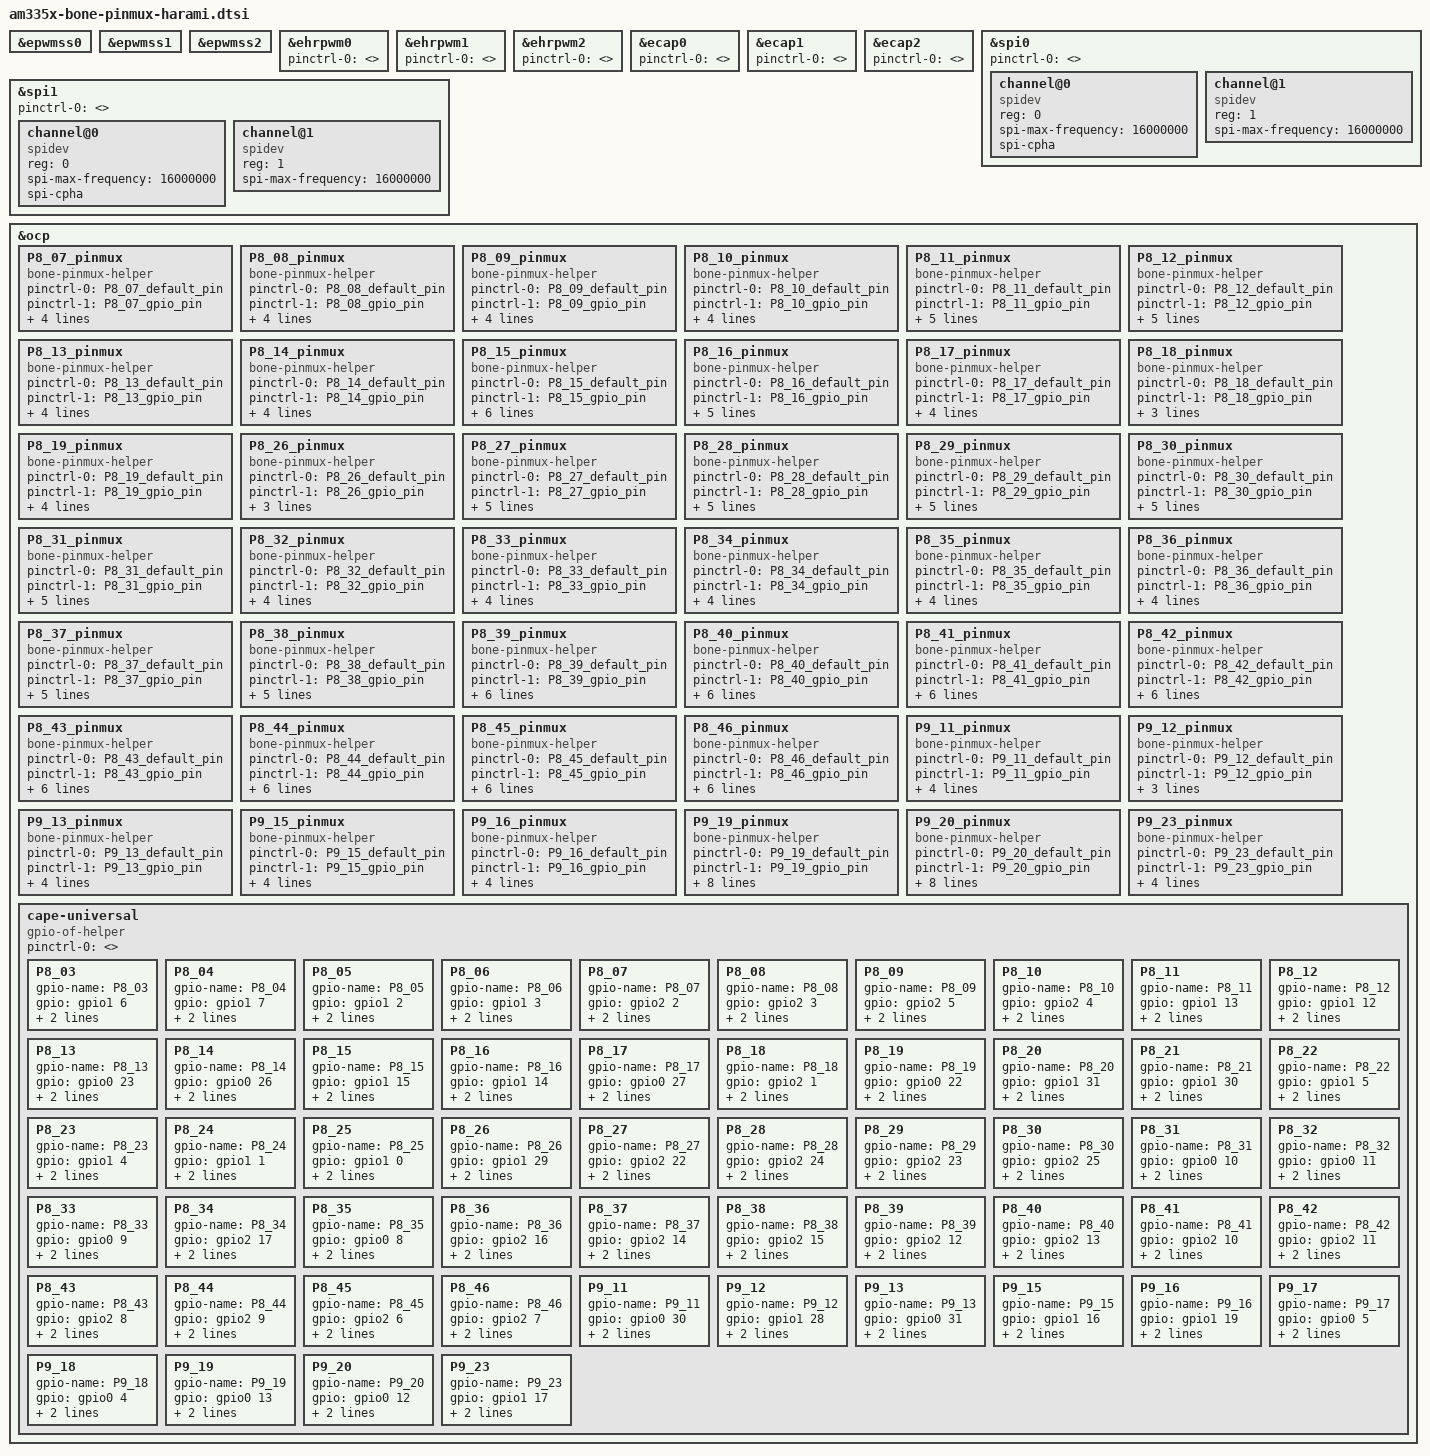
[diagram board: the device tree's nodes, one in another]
&epwmss0 {
	status = "okay";
};

&epwmss1 {
	status = "okay";
};

&epwmss2 {
	status = "okay";
};

&ehrpwm0 {
	status = "okay";
	pinctrl-names = "default";
	pinctrl-0 = <>;
};

&ehrpwm1 {
	status = "okay";
	pinctrl-names = "default";
	pinctrl-0 = <>;
};

&ehrpwm2 {
	status = "okay";
	pinctrl-names = "default";
	pinctrl-0 = <>;
};

&ecap0 {
	status = "okay";
	pinctrl-names = "default";
	pinctrl-0 = <>;
};

&ecap1 {
	status = "okay";
	pinctrl-names = "default";
	pinctrl-0 = <>;
};

&ecap2 {
	status = "okay";
	pinctrl-names = "default";
	pinctrl-0 = <>;
};

&spi0 {
	status = "okay";
	pinctrl-names = "default";
	pinctrl-0 = <>;

	channel@0 {
		#address-cells = <1>;
		#size-cells = <0>;

		compatible = "spidev";

		reg = <0>;
		spi-max-frequency = <16000000>;
		spi-cpha;
	};

	channel@1 {
		#address-cells = <1>;
		#size-cells = <0>;

		compatible = "spidev";

		reg = <1>;
		spi-max-frequency = <16000000>;
	};
};

&spi1 {
	status = "okay";
	pinctrl-names = "default";
	pinctrl-0 = <>;

	channel@0 {
		#address-cells = <1>;
		#size-cells = <0>;

		compatible = "spidev";

		reg = <0>;
		spi-max-frequency = <16000000>;
		spi-cpha;
	};

	channel@1 {
		#address-cells = <1>;
		#size-cells = <0>;

		compatible = "spidev";

		reg = <1>;
		spi-max-frequency = <16000000>;
	};
};

/**********************************************************************/
/* Pin Multiplex Helpers                                              */
/*                                                                    */
/* These provide userspace runtime pin configuration for the          */
/* BeagleBone cape expansion headers                                  */
/**********************************************************************/

&ocp {
	/************************/
	/* P8 Header */
	/************************/

	/* P8_01                GND */

	/* P8_02                GND */

	/* P8_03 (ZCZ ball R9) emmc */

	/* P8_04 (ZCZ ball T9) emmc */

	/* P8_05 (ZCZ ball R8) emmc */

	/* P8_06 (ZCZ ball T8) emmc */

	/* P8_07 (ZCZ ball R7) */
	P8_07_pinmux {
		compatible = "bone-pinmux-helper";
		status = "okay";
		pinctrl-names = "default", "gpio", "gpio_pu", "gpio_pd", "gpio_input", "timer";
		pinctrl-0 = <&P8_07_default_pin>;
		pinctrl-1 = <&P8_07_gpio_pin>;
		pinctrl-2 = <&P8_07_gpio_pu_pin>;
		pinctrl-3 = <&P8_07_gpio_pd_pin>;
		pinctrl-4 = <&P8_07_gpio_input_pin>;
		pinctrl-5 = <&P8_07_timer_pin>;
	};

	/* P8_08 (ZCZ ball T7) */
	P8_08_pinmux {
		compatible = "bone-pinmux-helper";
		status = "okay";
		pinctrl-names = "default", "gpio", "gpio_pu", "gpio_pd", "gpio_input", "timer";
		pinctrl-0 = <&P8_08_default_pin>;
		pinctrl-1 = <&P8_08_gpio_pin>;
		pinctrl-2 = <&P8_08_gpio_pu_pin>;
		pinctrl-3 = <&P8_08_gpio_pd_pin>;
		pinctrl-4 = <&P8_08_gpio_input_pin>;
		pinctrl-5 = <&P8_08_timer_pin>;
	};

	/* P8_09 (ZCZ ball T6) */
	P8_09_pinmux {
		compatible = "bone-pinmux-helper";
		status = "okay";
		pinctrl-names = "default", "gpio", "gpio_pu", "gpio_pd", "gpio_input", "timer";
		pinctrl-0 = <&P8_09_default_pin>;
		pinctrl-1 = <&P8_09_gpio_pin>;
		pinctrl-2 = <&P8_09_gpio_pu_pin>;
		pinctrl-3 = <&P8_09_gpio_pd_pin>;
		pinctrl-4 = <&P8_09_gpio_input_pin>;
		pinctrl-5 = <&P8_09_timer_pin>;
	};

	/* P8_10 (ZCZ ball U6) */
	P8_10_pinmux {
		compatible = "bone-pinmux-helper";
		status = "okay";
		pinctrl-names = "default", "gpio", "gpio_pu", "gpio_pd", "gpio_input", "timer";
		pinctrl-0 = <&P8_10_default_pin>;
		pinctrl-1 = <&P8_10_gpio_pin>;
		pinctrl-2 = <&P8_10_gpio_pu_pin>;
		pinctrl-3 = <&P8_10_gpio_pd_pin>;
		pinctrl-4 = <&P8_10_gpio_input_pin>;
		pinctrl-5 = <&P8_10_timer_pin>;
	};

	/* P8_11 (ZCZ ball R12) */
	P8_11_pinmux {
		compatible = "bone-pinmux-helper";
		status = "okay";
		pinctrl-names = "default", "gpio", "gpio_pu", "gpio_pd", "gpio_input", "qep", "pruout";
		pinctrl-0 = <&P8_11_default_pin>;
		pinctrl-1 = <&P8_11_gpio_pin>;
		pinctrl-2 = <&P8_11_gpio_pu_pin>;
		pinctrl-3 = <&P8_11_gpio_pd_pin>;
		pinctrl-4 = <&P8_11_gpio_input_pin>;
		pinctrl-5 = <&P8_11_qep_pin>;
		pinctrl-6 = <&P8_11_pruout_pin>;
	};

	/* P8_12 (ZCZ ball T12) */
	P8_12_pinmux {
		compatible = "bone-pinmux-helper";
		status = "okay";
		pinctrl-names = "default", "gpio", "gpio_pu", "gpio_pd", "gpio_input", "qep", "pruout";
		pinctrl-0 = <&P8_12_default_pin>;
		pinctrl-1 = <&P8_12_gpio_pin>;
		pinctrl-2 = <&P8_12_gpio_pu_pin>;
		pinctrl-3 = <&P8_12_gpio_pd_pin>;
		pinctrl-4 = <&P8_12_gpio_input_pin>;
		pinctrl-5 = <&P8_12_qep_pin>;
		pinctrl-6 = <&P8_12_pruout_pin>;
	};

	/* P8_13 (ZCZ ball T10) */
	P8_13_pinmux {
		compatible = "bone-pinmux-helper";
		status = "okay";
		pinctrl-names = "default", "gpio", "gpio_pu", "gpio_pd", "gpio_input", "pwm";
		pinctrl-0 = <&P8_13_default_pin>;
		pinctrl-1 = <&P8_13_gpio_pin>;
		pinctrl-2 = <&P8_13_gpio_pu_pin>;
		pinctrl-3 = <&P8_13_gpio_pd_pin>;
		pinctrl-4 = <&P8_13_gpio_input_pin>;
		pinctrl-5 = <&P8_13_pwm_pin>;
	};

	/* P8_14 (ZCZ ball T11) */
	P8_14_pinmux {
		compatible = "bone-pinmux-helper";
		status = "okay";
		pinctrl-names = "default", "gpio", "gpio_pu", "gpio_pd", "gpio_input", "pwm";
		pinctrl-0 = <&P8_14_default_pin>;
		pinctrl-1 = <&P8_14_gpio_pin>;
		pinctrl-2 = <&P8_14_gpio_pu_pin>;
		pinctrl-3 = <&P8_14_gpio_pd_pin>;
		pinctrl-4 = <&P8_14_gpio_input_pin>;
		pinctrl-5 = <&P8_14_pwm_pin>;
	};

	/* P8_15 (ZCZ ball U13) */
	P8_15_pinmux {
		compatible = "bone-pinmux-helper";
		status = "okay";
		pinctrl-names = "default", "gpio", "gpio_pu", "gpio_pd", "gpio_input", "qep", "pru_ecap", "pruin";
		pinctrl-0 = <&P8_15_default_pin>;
		pinctrl-1 = <&P8_15_gpio_pin>;
		pinctrl-2 = <&P8_15_gpio_pu_pin>;
		pinctrl-3 = <&P8_15_gpio_pd_pin>;
		pinctrl-4 = <&P8_15_gpio_input_pin>;
		pinctrl-5 = <&P8_15_qep_pin>;
		pinctrl-6 = <&P8_15_pru_ecap_pin>;
		pinctrl-7 = <&P8_15_pruin_pin>;
	};

	/* P8_16 (ZCZ ball V13) */
	P8_16_pinmux {
		compatible = "bone-pinmux-helper";
		status = "okay";
		pinctrl-names = "default", "gpio", "gpio_pu", "gpio_pd", "gpio_input", "qep", "pruin";
		pinctrl-0 = <&P8_16_default_pin>;
		pinctrl-1 = <&P8_16_gpio_pin>;
		pinctrl-2 = <&P8_16_gpio_pu_pin>;
		pinctrl-3 = <&P8_16_gpio_pd_pin>;
		pinctrl-4 = <&P8_16_gpio_input_pin>;
		pinctrl-5 = <&P8_16_qep_pin>;
		pinctrl-6 = <&P8_16_pruin_pin>;
	};

	/* P8_17 (ZCZ ball U12) */
	P8_17_pinmux {
		compatible = "bone-pinmux-helper";
		status = "okay";
		pinctrl-names = "default", "gpio", "gpio_pu", "gpio_pd", "gpio_input", "pwm";
		pinctrl-0 = <&P8_17_default_pin>;
		pinctrl-1 = <&P8_17_gpio_pin>;
		pinctrl-2 = <&P8_17_gpio_pu_pin>;
		pinctrl-3 = <&P8_17_gpio_pd_pin>;
		pinctrl-4 = <&P8_17_gpio_input_pin>;
		pinctrl-5 = <&P8_17_pwm_pin>;
	};

	/* P8_18 (ZCZ ball V12) */
	P8_18_pinmux {
		compatible = "bone-pinmux-helper";
		status = "okay";
		pinctrl-names = "default", "gpio", "gpio_pu", "gpio_pd", "gpio_input";
		pinctrl-0 = <&P8_18_default_pin>;
		pinctrl-1 = <&P8_18_gpio_pin>;
		pinctrl-2 = <&P8_18_gpio_pu_pin>;
		pinctrl-3 = <&P8_18_gpio_pd_pin>;
		pinctrl-4 = <&P8_18_gpio_input_pin>;
	};

	/* P8_19 (ZCZ ball U10) */
	P8_19_pinmux {
		compatible = "bone-pinmux-helper";
		status = "okay";
		pinctrl-names = "default", "gpio", "gpio_pu", "gpio_pd", "gpio_input", "pwm";
		pinctrl-0 = <&P8_19_default_pin>;
		pinctrl-1 = <&P8_19_gpio_pin>;
		pinctrl-2 = <&P8_19_gpio_pu_pin>;
		pinctrl-3 = <&P8_19_gpio_pd_pin>;
		pinctrl-4 = <&P8_19_gpio_input_pin>;
		pinctrl-5 = <&P8_19_pwm_pin>;
	};

	/* P8_20 (ZCZ ball V9) emmc */

	/* P8_21 (ZCZ ball U9) emmc */

	/* P8_22 (ZCZ ball V8) emmc */

	/* P8_23 (ZCZ ball U8) emmc */

	/* P8_24 (ZCZ ball V7) emmc */

	/* P8_25 (ZCZ ball U7) emmc */

	/* P8_26 (ZCZ ball V6) */
	P8_26_pinmux {
		compatible = "bone-pinmux-helper";
		status = "okay";
		pinctrl-names = "default", "gpio", "gpio_pu", "gpio_pd", "gpio_input";
		pinctrl-0 = <&P8_26_default_pin>;
		pinctrl-1 = <&P8_26_gpio_pin>;
		pinctrl-2 = <&P8_26_gpio_pu_pin>;
		pinctrl-3 = <&P8_26_gpio_pd_pin>;
		pinctrl-4 = <&P8_26_gpio_input_pin>;
	};

	/* P8_27 (ZCZ ball U5) hdmi */
	P8_27_pinmux {
		compatible = "bone-pinmux-helper";
		status = "okay";
		pinctrl-names = "default", "gpio", "gpio_pu", "gpio_pd", "gpio_input", "pruout", "pruin";
		pinctrl-0 = <&P8_27_default_pin>;
		pinctrl-1 = <&P8_27_gpio_pin>;
		pinctrl-2 = <&P8_27_gpio_pu_pin>;
		pinctrl-3 = <&P8_27_gpio_pd_pin>;
		pinctrl-4 = <&P8_27_gpio_input_pin>;
		pinctrl-5 = <&P8_27_pruout_pin>;
		pinctrl-6 = <&P8_27_pruin_pin>;
	};

	/* P8_28 (ZCZ ball V5) hdmi */
	P8_28_pinmux {
		compatible = "bone-pinmux-helper";
		status = "okay";
		pinctrl-names = "default", "gpio", "gpio_pu", "gpio_pd", "gpio_input", "pruout", "pruin";
		pinctrl-0 = <&P8_28_default_pin>;
		pinctrl-1 = <&P8_28_gpio_pin>;
		pinctrl-2 = <&P8_28_gpio_pu_pin>;
		pinctrl-3 = <&P8_28_gpio_pd_pin>;
		pinctrl-4 = <&P8_28_gpio_input_pin>;
		pinctrl-5 = <&P8_28_pruout_pin>;
		pinctrl-6 = <&P8_28_pruin_pin>;
	};

	/* P8_29 (ZCZ ball R5) hdmi */
	P8_29_pinmux {
		compatible = "bone-pinmux-helper";
		status = "okay";
		pinctrl-names = "default", "gpio", "gpio_pu", "gpio_pd", "gpio_input", "pruout", "pruin";
		pinctrl-0 = <&P8_29_default_pin>;
		pinctrl-1 = <&P8_29_gpio_pin>;
		pinctrl-2 = <&P8_29_gpio_pu_pin>;
		pinctrl-3 = <&P8_29_gpio_pd_pin>;
		pinctrl-4 = <&P8_29_gpio_input_pin>;
		pinctrl-5 = <&P8_29_pruout_pin>;
		pinctrl-6 = <&P8_29_pruin_pin>;
	};

	/* P8_30 (ZCZ ball R6) hdmi */
	P8_30_pinmux {
		compatible = "bone-pinmux-helper";
		status = "okay";
		pinctrl-names = "default", "gpio", "gpio_pu", "gpio_pd", "gpio_input", "pruout", "pruin";
		pinctrl-0 = <&P8_30_default_pin>;
		pinctrl-1 = <&P8_30_gpio_pin>;
		pinctrl-2 = <&P8_30_gpio_pu_pin>;
		pinctrl-3 = <&P8_30_gpio_pd_pin>;
		pinctrl-4 = <&P8_30_gpio_input_pin>;
		pinctrl-5 = <&P8_30_pruout_pin>;
		pinctrl-6 = <&P8_30_pruin_pin>;
	};

	/* P8_31 (ZCZ ball V4) hdmi */
	P8_31_pinmux {
		compatible = "bone-pinmux-helper";
		status = "okay";
		pinctrl-names = "default", "gpio", "gpio_pu", "gpio_pd", "gpio_input", "uart", "qep";
		pinctrl-0 = <&P8_31_default_pin>;
		pinctrl-1 = <&P8_31_gpio_pin>;
		pinctrl-2 = <&P8_31_gpio_pu_pin>;
		pinctrl-3 = <&P8_31_gpio_pd_pin>;
		pinctrl-4 = <&P8_31_gpio_input_pin>;
		pinctrl-5 = <&P8_31_uart_pin>;
		pinctrl-6 = <&P8_31_qep_pin>;
	};

	/* P8_32 (ZCZ ball T5) hdmi */
	P8_32_pinmux {
		compatible = "bone-pinmux-helper";
		status = "okay";
		pinctrl-names = "default", "gpio", "gpio_pu", "gpio_pd", "gpio_input", "qep";
		pinctrl-0 = <&P8_32_default_pin>;
		pinctrl-1 = <&P8_32_gpio_pin>;
		pinctrl-2 = <&P8_32_gpio_pu_pin>;
		pinctrl-3 = <&P8_32_gpio_pd_pin>;
		pinctrl-4 = <&P8_32_gpio_input_pin>;
		pinctrl-5 = <&P8_32_qep_pin>;
	};

	/* P8_33 (ZCZ ball V3) hdmi */
	P8_33_pinmux {
		compatible = "bone-pinmux-helper";
		status = "okay";
		pinctrl-names = "default", "gpio", "gpio_pu", "gpio_pd", "gpio_input", "qep";
		pinctrl-0 = <&P8_33_default_pin>;
		pinctrl-1 = <&P8_33_gpio_pin>;
		pinctrl-2 = <&P8_33_gpio_pu_pin>;
		pinctrl-3 = <&P8_33_gpio_pd_pin>;
		pinctrl-4 = <&P8_33_gpio_input_pin>;
		pinctrl-5 = <&P8_33_qep_pin>;
	};

	/* P8_34 (ZCZ ball U4) hdmi */
	P8_34_pinmux {
		compatible = "bone-pinmux-helper";
		status = "okay";
		pinctrl-names = "default", "gpio", "gpio_pu", "gpio_pd", "gpio_input", "pwm";
		pinctrl-0 = <&P8_34_default_pin>;
		pinctrl-1 = <&P8_34_gpio_pin>;
		pinctrl-2 = <&P8_34_gpio_pu_pin>;
		pinctrl-3 = <&P8_34_gpio_pd_pin>;
		pinctrl-4 = <&P8_34_gpio_input_pin>;
		pinctrl-5 = <&P8_34_pwm_pin>;
	};

	/* P8_35 (ZCZ ball V2) hdmi */
	P8_35_pinmux {
		compatible = "bone-pinmux-helper";
		status = "okay";
		pinctrl-names = "default", "gpio", "gpio_pu", "gpio_pd", "gpio_input", "qep";
		pinctrl-0 = <&P8_35_default_pin>;
		pinctrl-1 = <&P8_35_gpio_pin>;
		pinctrl-2 = <&P8_35_gpio_pu_pin>;
		pinctrl-3 = <&P8_35_gpio_pd_pin>;
		pinctrl-4 = <&P8_35_gpio_input_pin>;
		pinctrl-5 = <&P8_35_qep_pin>;
	};

	/* P8_36 (ZCZ ball U3) hdmi */
	P8_36_pinmux {
		compatible = "bone-pinmux-helper";
		status = "okay";
		pinctrl-names = "default", "gpio", "gpio_pu", "gpio_pd", "gpio_input", "pwm";
		pinctrl-0 = <&P8_36_default_pin>;
		pinctrl-1 = <&P8_36_gpio_pin>;
		pinctrl-2 = <&P8_36_gpio_pu_pin>;
		pinctrl-3 = <&P8_36_gpio_pd_pin>;
		pinctrl-4 = <&P8_36_gpio_input_pin>;
		pinctrl-5 = <&P8_36_pwm_pin>;
	};

	/* P8_37 (ZCZ ball U1) hdmi */
	P8_37_pinmux {
		compatible = "bone-pinmux-helper";
		status = "okay";
		pinctrl-names = "default", "gpio", "gpio_pu", "gpio_pd", "gpio_input", "uart", "pwm";
		pinctrl-0 = <&P8_37_default_pin>;
		pinctrl-1 = <&P8_37_gpio_pin>;
		pinctrl-2 = <&P8_37_gpio_pu_pin>;
		pinctrl-3 = <&P8_37_gpio_pd_pin>;
		pinctrl-4 = <&P8_37_gpio_input_pin>;
		pinctrl-5 = <&P8_37_uart_pin>;
		pinctrl-6 = <&P8_37_pwm_pin>;
	};

	/* P8_38 (ZCZ ball U2) hdmi */
	P8_38_pinmux {
		compatible = "bone-pinmux-helper";
		status = "okay";
		pinctrl-names = "default", "gpio", "gpio_pu", "gpio_pd", "gpio_input", "uart", "pwm";
		pinctrl-0 = <&P8_38_default_pin>;
		pinctrl-1 = <&P8_38_gpio_pin>;
		pinctrl-2 = <&P8_38_gpio_pu_pin>;
		pinctrl-3 = <&P8_38_gpio_pd_pin>;
		pinctrl-4 = <&P8_38_gpio_input_pin>;
		pinctrl-5 = <&P8_38_uart_pin>;
		pinctrl-6 = <&P8_38_pwm_pin>;
	};

	/* P8_39 (ZCZ ball T3) hdmi */
	P8_39_pinmux {
		compatible = "bone-pinmux-helper";
		status = "okay";
		pinctrl-names = "default", "gpio", "gpio_pu", "gpio_pd", "gpio_input", "qep", "pruout", "pruin";
		pinctrl-0 = <&P8_39_default_pin>;
		pinctrl-1 = <&P8_39_gpio_pin>;
		pinctrl-2 = <&P8_39_gpio_pu_pin>;
		pinctrl-3 = <&P8_39_gpio_pd_pin>;
		pinctrl-4 = <&P8_39_gpio_input_pin>;
		pinctrl-5 = <&P8_39_qep_pin>;
		pinctrl-6 = <&P8_39_pruout_pin>;
		pinctrl-7 = <&P8_39_pruin_pin>;
	};

	/* P8_40 (ZCZ ball T4) hdmi */
	P8_40_pinmux {
		compatible = "bone-pinmux-helper";
		status = "okay";
		pinctrl-names = "default", "gpio", "gpio_pu", "gpio_pd", "gpio_input", "qep", "pruout", "pruin";
		pinctrl-0 = <&P8_40_default_pin>;
		pinctrl-1 = <&P8_40_gpio_pin>;
		pinctrl-2 = <&P8_40_gpio_pu_pin>;
		pinctrl-3 = <&P8_40_gpio_pd_pin>;
		pinctrl-4 = <&P8_40_gpio_input_pin>;
		pinctrl-5 = <&P8_40_qep_pin>;
		pinctrl-6 = <&P8_40_pruout_pin>;
		pinctrl-7 = <&P8_40_pruin_pin>;
	};

	/* P8_41 (ZCZ ball T1) hdmi */
	P8_41_pinmux {
		compatible = "bone-pinmux-helper";
		status = "okay";
		pinctrl-names = "default", "gpio", "gpio_pu", "gpio_pd", "gpio_input", "qep", "pruout", "pruin";
		pinctrl-0 = <&P8_41_default_pin>;
		pinctrl-1 = <&P8_41_gpio_pin>;
		pinctrl-2 = <&P8_41_gpio_pu_pin>;
		pinctrl-3 = <&P8_41_gpio_pd_pin>;
		pinctrl-4 = <&P8_41_gpio_input_pin>;
		pinctrl-5 = <&P8_41_qep_pin>;
		pinctrl-6 = <&P8_41_pruout_pin>;
		pinctrl-7 = <&P8_41_pruin_pin>;
	};

	/* P8_42 (ZCZ ball T2) hdmi */
	P8_42_pinmux {
		compatible = "bone-pinmux-helper";
		status = "okay";
		pinctrl-names = "default", "gpio", "gpio_pu", "gpio_pd", "gpio_input", "qep", "pruout", "pruin";
		pinctrl-0 = <&P8_42_default_pin>;
		pinctrl-1 = <&P8_42_gpio_pin>;
		pinctrl-2 = <&P8_42_gpio_pu_pin>;
		pinctrl-3 = <&P8_42_gpio_pd_pin>;
		pinctrl-4 = <&P8_42_gpio_input_pin>;
		pinctrl-5 = <&P8_42_qep_pin>;
		pinctrl-6 = <&P8_42_pruout_pin>;
		pinctrl-7 = <&P8_42_pruin_pin>;
	};

	/* P8_43 (ZCZ ball R3) hdmi */
	P8_43_pinmux {
		compatible = "bone-pinmux-helper";
		status = "okay";
		pinctrl-names = "default", "gpio", "gpio_pu", "gpio_pd", "gpio_input", "pwm", "pruout", "pruin";
		pinctrl-0 = <&P8_43_default_pin>;
		pinctrl-1 = <&P8_43_gpio_pin>;
		pinctrl-2 = <&P8_43_gpio_pu_pin>;
		pinctrl-3 = <&P8_43_gpio_pd_pin>;
		pinctrl-4 = <&P8_43_gpio_input_pin>;
		pinctrl-5 = <&P8_43_pwm_pin>;
		pinctrl-6 = <&P8_43_pruout_pin>;
		pinctrl-7 = <&P8_43_pruin_pin>;
	};

	/* P8_44 (ZCZ ball R4) hdmi */
	P8_44_pinmux {
		compatible = "bone-pinmux-helper";
		status = "okay";
		pinctrl-names = "default", "gpio", "gpio_pu", "gpio_pd", "gpio_input", "pwm", "pruout", "pruin";
		pinctrl-0 = <&P8_44_default_pin>;
		pinctrl-1 = <&P8_44_gpio_pin>;
		pinctrl-2 = <&P8_44_gpio_pu_pin>;
		pinctrl-3 = <&P8_44_gpio_pd_pin>;
		pinctrl-4 = <&P8_44_gpio_input_pin>;
		pinctrl-5 = <&P8_44_pwm_pin>;
		pinctrl-6 = <&P8_44_pruout_pin>;
		pinctrl-7 = <&P8_44_pruin_pin>;
	};

	/* P8_45 (ZCZ ball R1) hdmi */
	P8_45_pinmux {
		compatible = "bone-pinmux-helper";
		status = "okay";
		pinctrl-names = "default", "gpio", "gpio_pu", "gpio_pd", "gpio_input", "pwm", "pruout", "pruin";
		pinctrl-0 = <&P8_45_default_pin>;
		pinctrl-1 = <&P8_45_gpio_pin>;
		pinctrl-2 = <&P8_45_gpio_pu_pin>;
		pinctrl-3 = <&P8_45_gpio_pd_pin>;
		pinctrl-4 = <&P8_45_gpio_input_pin>;
		pinctrl-5 = <&P8_45_pwm_pin>;
		pinctrl-6 = <&P8_45_pruout_pin>;
		pinctrl-7 = <&P8_45_pruin_pin>;
	};

	/* P8_46 (ZCZ ball R2) hdmi */
	P8_46_pinmux {
		compatible = "bone-pinmux-helper";
		status = "okay";
		pinctrl-names = "default", "gpio", "gpio_pu", "gpio_pd", "gpio_input", "pwm", "pruout", "pruin";
		pinctrl-0 = <&P8_46_default_pin>;
		pinctrl-1 = <&P8_46_gpio_pin>;
		pinctrl-2 = <&P8_46_gpio_pu_pin>;
		pinctrl-3 = <&P8_46_gpio_pd_pin>;
		pinctrl-4 = <&P8_46_gpio_input_pin>;
		pinctrl-5 = <&P8_46_pwm_pin>;
		pinctrl-6 = <&P8_46_pruout_pin>;
		pinctrl-7 = <&P8_46_pruin_pin>;
	};

	/************************/
	/* P9 Header */
	/************************/

	/* P9_01                GND */

	/* P9_02                GND */

	/* P9_03                3V3 */

	/* P9_04                3V3 */

	/* P9_05                VDD_5V */

	/* P9_06                VDD_5V */

	/* P9_07                SYS_5V */

	/* P9_08                SYS_5V */

	/* P9_09                PWR_BUT */

	/* P9_10                RSTn */

	/* P9_11 (ZCZ ball T17) */
	P9_11_pinmux {
		compatible = "bone-pinmux-helper";
		status = "okay";
		pinctrl-names = "default", "gpio", "gpio_pu", "gpio_pd", "gpio_input", "uart";
		pinctrl-0 = <&P9_11_default_pin>;
		pinctrl-1 = <&P9_11_gpio_pin>;
		pinctrl-2 = <&P9_11_gpio_pu_pin>;
		pinctrl-3 = <&P9_11_gpio_pd_pin>;
		pinctrl-4 = <&P9_11_gpio_input_pin>;
		pinctrl-5 = <&P9_11_uart_pin>;
	};

	/* P9_12 (ZCZ ball U18) */
	P9_12_pinmux {
		compatible = "bone-pinmux-helper";
		status = "okay";
		pinctrl-names = "default", "gpio", "gpio_pu", "gpio_pd", "gpio_input";
		pinctrl-0 = <&P9_12_default_pin>;
		pinctrl-1 = <&P9_12_gpio_pin>;
		pinctrl-2 = <&P9_12_gpio_pu_pin>;
		pinctrl-3 = <&P9_12_gpio_pd_pin>;
		pinctrl-4 = <&P9_12_gpio_input_pin>;
	};

	/* P9_13 (ZCZ ball U17) */
	P9_13_pinmux {
		compatible = "bone-pinmux-helper";
		status = "okay";
		pinctrl-names = "default", "gpio", "gpio_pu", "gpio_pd", "gpio_input", "uart";
		pinctrl-0 = <&P9_13_default_pin>;
		pinctrl-1 = <&P9_13_gpio_pin>;
		pinctrl-2 = <&P9_13_gpio_pu_pin>;
		pinctrl-3 = <&P9_13_gpio_pd_pin>;
		pinctrl-4 = <&P9_13_gpio_input_pin>;
		pinctrl-5 = <&P9_13_uart_pin>;
	};

	/* P9_14 (ZCZ ball U14) */

	/* P9_15 (ZCZ ball R13) */
	P9_15_pinmux {
		compatible = "bone-pinmux-helper";
		status = "okay";
		pinctrl-names = "default", "gpio", "gpio_pu", "gpio_pd", "gpio_input", "pwm";
		pinctrl-0 = <&P9_15_default_pin>;
		pinctrl-1 = <&P9_15_gpio_pin>;
		pinctrl-2 = <&P9_15_gpio_pu_pin>;
		pinctrl-3 = <&P9_15_gpio_pd_pin>;
		pinctrl-4 = <&P9_15_gpio_input_pin>;
		pinctrl-5 = <&P9_15_pwm_pin>;
	};

	/* P9_16 (ZCZ ball T14) */
	P9_16_pinmux {
		compatible = "bone-pinmux-helper";
		status = "okay";
		pinctrl-names = "default", "gpio", "gpio_pu", "gpio_pd", "gpio_input", "pwm";
		pinctrl-0 = <&P9_16_default_pin>;
		pinctrl-1 = <&P9_16_gpio_pin>;
		pinctrl-2 = <&P9_16_gpio_pu_pin>;
		pinctrl-3 = <&P9_16_gpio_pd_pin>;
		pinctrl-4 = <&P9_16_gpio_input_pin>;
		pinctrl-5 = <&P9_16_pwm_pin>;
	};

	/* P9_17 (ZCZ ball A16) */

	/* P9_18 (ZCZ ball B16) */

	/* P9_19 (ZCZ ball D17) i2c */
	P9_19_pinmux {
		compatible = "bone-pinmux-helper";
		status = "okay";
		pinctrl-names = "default", "gpio", "gpio_pu", "gpio_pd", "gpio_input", "spi_cs", "can", "i2c", "pru_uart", "timer";
		pinctrl-0 = <&P9_19_default_pin>;
		pinctrl-1 = <&P9_19_gpio_pin>;
		pinctrl-2 = <&P9_19_gpio_pu_pin>;
		pinctrl-3 = <&P9_19_gpio_pd_pin>;
		pinctrl-4 = <&P9_19_gpio_input_pin>;
		pinctrl-5 = <&P9_19_spi_cs_pin>;
		pinctrl-6 = <&P9_19_can_pin>;
		pinctrl-7 = <&P9_19_i2c_pin>;
		pinctrl-8 = <&P9_19_pru_uart_pin>;
		pinctrl-9 = <&P9_19_timer_pin>;
	};

	/* P9_20 (ZCZ ball D18) i2c */
	P9_20_pinmux {
		compatible = "bone-pinmux-helper";
		status = "okay";
		pinctrl-names = "default", "gpio", "gpio_pu", "gpio_pd", "gpio_input", "spi_cs", "can", "i2c", "pru_uart", "timer";
		pinctrl-0 = <&P9_20_default_pin>;
		pinctrl-1 = <&P9_20_gpio_pin>;
		pinctrl-2 = <&P9_20_gpio_pu_pin>;
		pinctrl-3 = <&P9_20_gpio_pd_pin>;
		pinctrl-4 = <&P9_20_gpio_input_pin>;
		pinctrl-5 = <&P9_20_spi_cs_pin>;
		pinctrl-6 = <&P9_20_can_pin>;
		pinctrl-7 = <&P9_20_i2c_pin>;
		pinctrl-8 = <&P9_20_pru_uart_pin>;
		pinctrl-9 = <&P9_20_timer_pin>;
	};

	/* P9_21 (ZCZ ball B17) */

	/* P9_22 (ZCZ ball A17) */

	/* P9_23 (ZCZ ball V14) */
	P9_23_pinmux {
		compatible = "bone-pinmux-helper";
		status = "okay";
		pinctrl-names = "default", "gpio", "gpio_pu", "gpio_pd", "gpio_input", "pwm";
		pinctrl-0 = <&P9_23_default_pin>;
		pinctrl-1 = <&P9_23_gpio_pin>;
		pinctrl-2 = <&P9_23_gpio_pu_pin>;
		pinctrl-3 = <&P9_23_gpio_pd_pin>;
		pinctrl-4 = <&P9_23_gpio_input_pin>;
		pinctrl-5 = <&P9_23_pwm_pin>;
	};

	/* P9_24 (ZCZ ball D15) */

	/* P9_25 (ZCZ ball A14) audio */

	/* P9_26 (ZCZ ball D16) */

	/* P9_27 (ZCZ ball C13) */

	/* P9_28 (ZCZ ball C12) audio */

	/* P9_29 (ZCZ ball B13) audio */

	/* P9_30 (ZCZ ball D12) */

	/* P9_31 (ZCZ ball A13) audio */

	/* P9_32                VADC */

	/* P9_33 (ZCZ ball C8)  AIN4         */

	/* P9_34                AGND */

	/* P9_35 (ZCZ ball A8)  AIN6         */

	/* P9_36 (ZCZ ball B8)  AIN5         */

	/* P9_37 (ZCZ ball B7)  AIN2         */

	/* P9_38 (ZCZ ball A7)  AIN3         */

	/* P9_39 (ZCZ ball B6)  AIN0         */

	/* P9_40 (ZCZ ball C7)  AIN1         */

	/* P9_41 (ZCZ ball D14) */

	/* P9_41.1 */
	/* P9_91 (ZCZ ball D13) */

	/* P9_42 (ZCZ ball C18) */

	/* P9_42.1 */
	/* P9_92 (ZCZ ball B12) */

	/* P9_43                GND */

	/* P9_44                GND */

	/* P9_45                GND */

	/* P9_46                GND */


	cape-universal {
		compatible = "gpio-of-helper";
		status = "okay";
		pinctrl-names = "default";
		pinctrl-0 = <>;

		P8_03 {
			gpio-name = "P8_03";
			gpio = <&gpio1 6 0>;
			input;
			dir-changeable;
		};

		P8_04 {
			gpio-name = "P8_04";
			gpio = <&gpio1 7 0>;
			input;
			dir-changeable;
		};

		P8_05 {
			gpio-name = "P8_05";
			gpio = <&gpio1 2 0>;
			input;
			dir-changeable;
		};

		P8_06 {
			gpio-name = "P8_06";
			gpio = <&gpio1 3 0>;
			input;
			dir-changeable;
		};

		P8_07 {
			gpio-name = "P8_07";
			gpio = <&gpio2 2 0>;
			input;
			dir-changeable;
		};

		P8_08 {
			gpio-name = "P8_08";
			gpio = <&gpio2 3 0>;
			input;
			dir-changeable;
		};

		P8_09 {
			gpio-name = "P8_09";
			gpio = <&gpio2 5 0>;
			input;
			dir-changeable;
		};

		P8_10 {
			gpio-name = "P8_10";
			gpio = <&gpio2 4 0>;
			input;
			dir-changeable;
		};

		P8_11 {
			gpio-name = "P8_11";
			gpio = <&gpio1 13 0>;
			input;
			dir-changeable;
		};

		P8_12 {
			gpio-name = "P8_12";
			gpio = <&gpio1 12 0>;
			input;
			dir-changeable;
		};

		P8_13 {
			gpio-name = "P8_13";
			gpio = <&gpio0 23 0>;
			input;
			dir-changeable;
		};

		P8_14 {
			gpio-name = "P8_14";
			gpio = <&gpio0 26 0>;
			input;
			dir-changeable;
		};

		P8_15 {
			gpio-name = "P8_15";
			gpio = <&gpio1 15 0>;
			input;
			dir-changeable;
		};

		P8_16 {
			gpio-name = "P8_16";
			gpio = <&gpio1 14 0>;
			input;
			dir-changeable;
		};

		P8_17 {
			gpio-name = "P8_17";
			gpio = <&gpio0 27 0>;
			input;
			dir-changeable;
		};

		P8_18 {
			gpio-name = "P8_18";
			gpio = <&gpio2 1 0>;
			input;
			dir-changeable;
		};

		P8_19 {
			gpio-name = "P8_19";
			gpio = <&gpio0 22 0>;
			input;
			dir-changeable;
		};

		P8_20 {
			gpio-name = "P8_20";
			gpio = <&gpio1 31 0>;
			input;
			dir-changeable;
		};

		P8_21 {
			gpio-name = "P8_21";
			gpio = <&gpio1 30 0>;
			input;
			dir-changeable;
		};

		P8_22 {
			gpio-name = "P8_22";
			gpio = <&gpio1 5 0>;
			input;
			dir-changeable;
		};

		P8_23 {
			gpio-name = "P8_23";
			gpio = <&gpio1 4 0>;
			input;
			dir-changeable;
		};

		P8_24 {
			gpio-name = "P8_24";
			gpio = <&gpio1 1 0>;
			input;
			dir-changeable;
		};

		P8_25 {
			gpio-name = "P8_25";
			gpio = <&gpio1 0 0>;
			input;
			dir-changeable;
		};

		P8_26 {
			gpio-name = "P8_26";
			gpio = <&gpio1 29 0>;
			input;
			dir-changeable;
		};

		P8_27 {
			gpio-name = "P8_27";
			gpio = <&gpio2 22 0>;
			input;
			dir-changeable;
		};

		P8_28 {
			gpio-name = "P8_28";
			gpio = <&gpio2 24 0>;
			input;
			dir-changeable;
		};

		P8_29 {
			gpio-name = "P8_29";
			gpio = <&gpio2 23 0>;
			input;
			dir-changeable;
		};

		P8_30 {
			gpio-name = "P8_30";
			gpio = <&gpio2 25 0>;
			input;
			dir-changeable;
		};

		P8_31 {
			gpio-name = "P8_31";
			gpio = <&gpio0 10 0>;
			input;
			dir-changeable;
		};

		P8_32 {
			gpio-name = "P8_32";
			gpio = <&gpio0 11 0>;
			input;
			dir-changeable;
		};

		P8_33 {
			gpio-name = "P8_33";
			gpio = <&gpio0 9 0>;
			input;
			dir-changeable;
		};

		P8_34 {
			gpio-name = "P8_34";
			gpio = <&gpio2 17 0>;
			input;
			dir-changeable;
		};

		P8_35 {
			gpio-name = "P8_35";
			gpio = <&gpio0 8 0>;
			input;
			dir-changeable;
		};

		P8_36 {
			gpio-name = "P8_36";
			gpio = <&gpio2 16 0>;
			input;
			dir-changeable;
		};

		P8_37 {
			gpio-name = "P8_37";
			gpio = <&gpio2 14 0>;
			input;
			dir-changeable;
		};

		P8_38 {
			gpio-name = "P8_38";
			gpio = <&gpio2 15 0>;
			input;
			dir-changeable;
		};

		P8_39 {
			gpio-name = "P8_39";
			gpio = <&gpio2 12 0>;
			input;
			dir-changeable;
		};

		P8_40 {
			gpio-name = "P8_40";
			gpio = <&gpio2 13 0>;
			input;
			dir-changeable;
		};

		P8_41 {
			gpio-name = "P8_41";
			gpio = <&gpio2 10 0>;
			input;
			dir-changeable;
		};

		P8_42 {
			gpio-name = "P8_42";
			gpio = <&gpio2 11 0>;
			input;
			dir-changeable;
		};

		P8_43 {
			gpio-name = "P8_43";
			gpio = <&gpio2 8 0>;
			input;
			dir-changeable;
		};

		P8_44 {
			gpio-name = "P8_44";
			gpio = <&gpio2 9 0>;
			input;
			dir-changeable;
		};

		P8_45 {
			gpio-name = "P8_45";
			gpio = <&gpio2 6 0>;
			input;
			dir-changeable;
		};

		P8_46 {
			gpio-name = "P8_46";
			gpio = <&gpio2 7 0>;
			input;
			dir-changeable;
		};

		P9_11 {
			gpio-name = "P9_11";
			gpio = <&gpio0 30 0>;
			input;
			dir-changeable;
		};

		P9_12 {
			gpio-name = "P9_12";
			gpio = <&gpio1 28 0>;
			input;
			dir-changeable;
		};

		P9_13 {
			gpio-name = "P9_13";
			gpio = <&gpio0 31 0>;
			input;
			dir-changeable;
		};

		P9_15 {
			gpio-name = "P9_15";
			gpio = <&gpio1 16 0>;
			input;
			dir-changeable;
		};

		P9_16 {
			gpio-name = "P9_16";
			gpio = <&gpio1 19 0>;
			input;
			dir-changeable;
		};

		P9_17 {
			gpio-name = "P9_17";
			gpio = <&gpio0 5 0>;
			input;
			dir-changeable;
		};

		P9_18 {
			gpio-name = "P9_18";
			gpio = <&gpio0 4 0>;
			input;
			dir-changeable;
		};

		P9_19 {
			gpio-name = "P9_19";
			gpio = <&gpio0 13 0>;
			input;
			dir-changeable;
		};

		P9_20 {
			gpio-name = "P9_20";
			gpio = <&gpio0 12 0>;
			input;
			dir-changeable;
		};

		P9_23 {
			gpio-name = "P9_23";
			gpio = <&gpio1 17 0>;
			input;
			dir-changeable;
		};
	};
};
